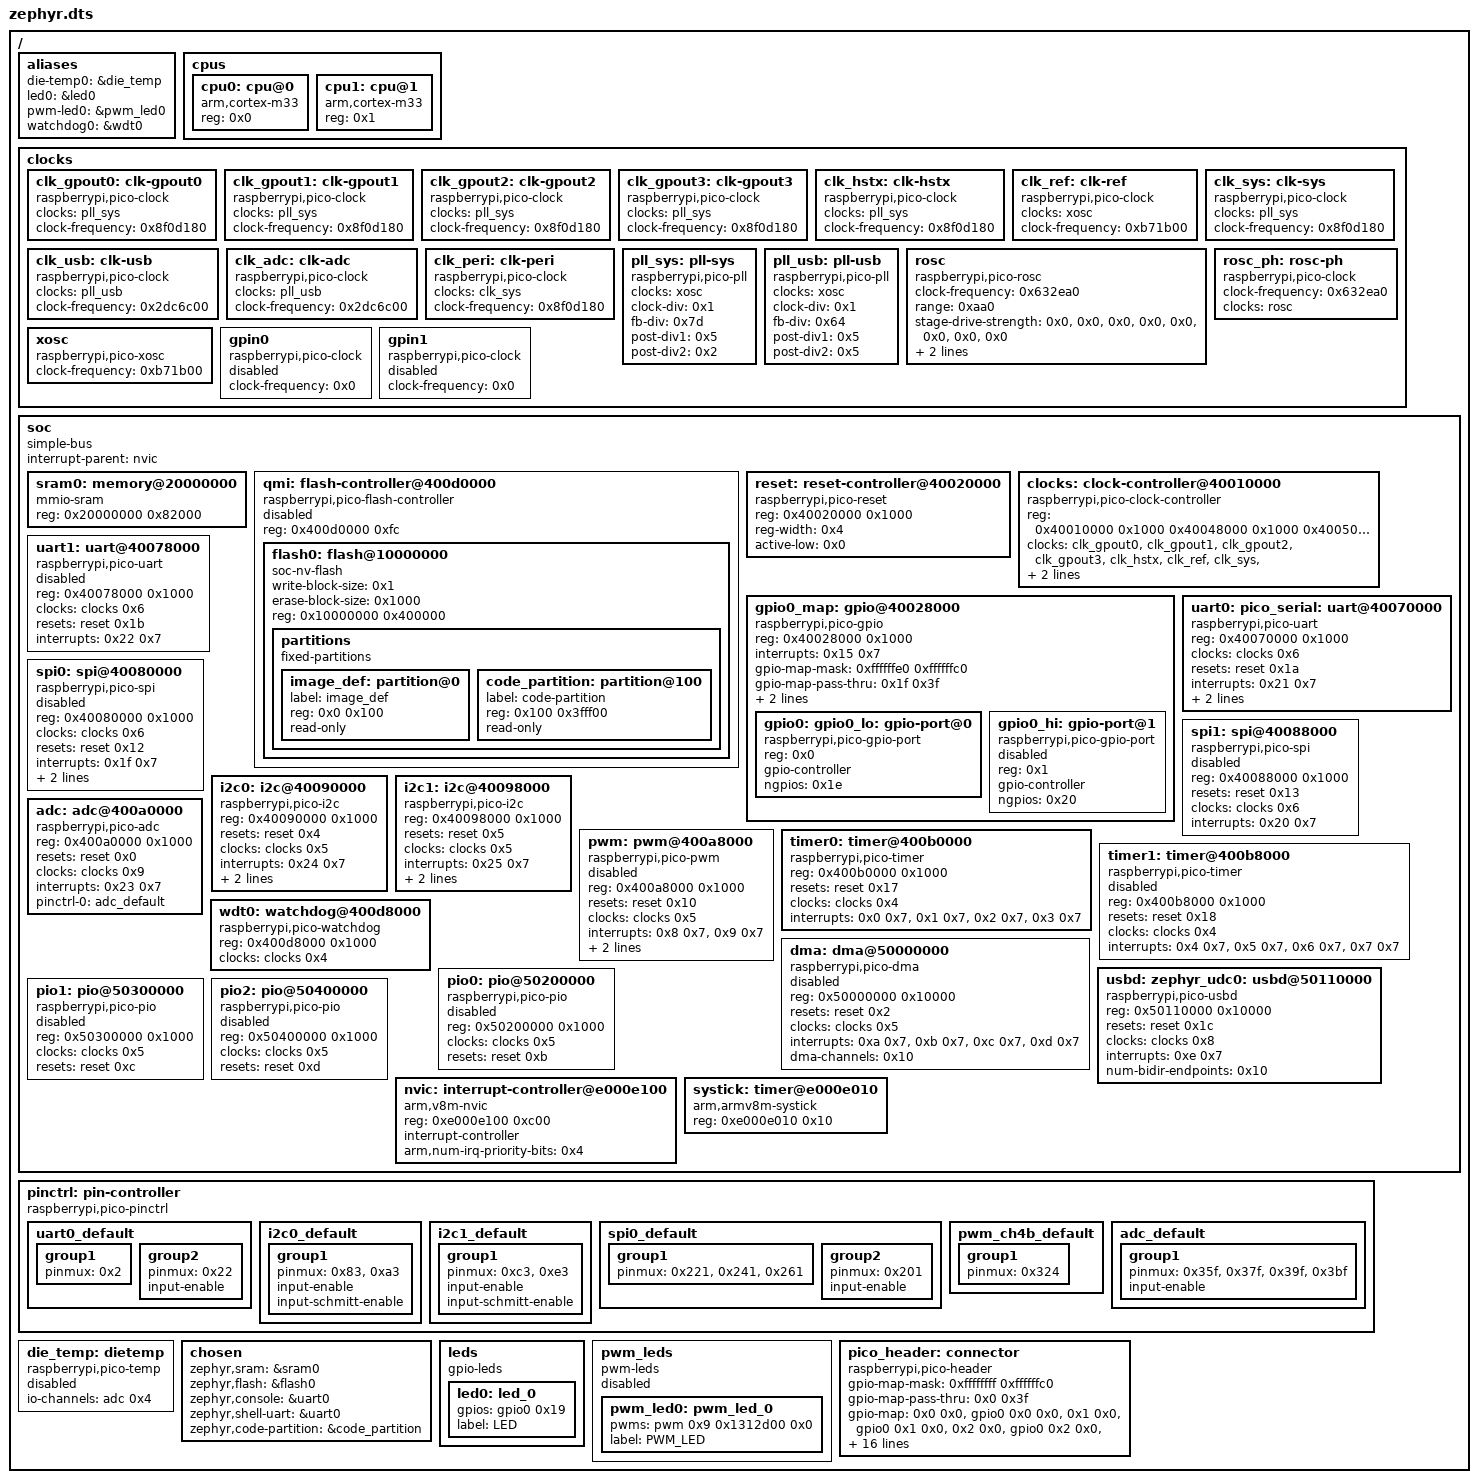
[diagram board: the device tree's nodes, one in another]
/dts-v1/;

/* node '/' defined in deps/zephyr/dts/arm/raspberrypi/rpi_pico/rp2350.dtsi:19 */
/ {
	#address-cells = < 0x1 >; /* in deps/zephyr/dts/common/skeleton.dtsi:10 */
	#size-cells = < 0x1 >;    /* in deps/zephyr/dts/common/skeleton.dtsi:11 */

	/* node '/aliases' defined in deps/zephyr/dts/arm/raspberrypi/rpi_pico/rp2350.dtsi:20 */
	aliases {
		die-temp0 = &die_temp; /* in deps/zephyr/dts/arm/raspberrypi/rpi_pico/rp2350.dtsi:21 */
		led0 = &led0;          /* in deps/zephyr/boards/raspberrypi/common/rpi_pico-led.dtsi:27 */
		pwm-led0 = &pwm_led0;  /* in deps/zephyr/boards/raspberrypi/common/rpi_pico-led.dtsi:28 */
		watchdog0 = &wdt0;     /* in deps/zephyr/boards/raspberrypi/rpi_pico2/rpi_pico2.dtsi:25 */
	};

	/* node '/cpus' defined in deps/zephyr/dts/arm/raspberrypi/rpi_pico/rp2350.dtsi:24 */
	cpus {
		#address-cells = < 0x1 >; /* in deps/zephyr/dts/arm/raspberrypi/rpi_pico/rp2350.dtsi:25 */
		#size-cells = < 0x0 >;    /* in deps/zephyr/dts/arm/raspberrypi/rpi_pico/rp2350.dtsi:26 */

		/* node '/cpus/cpu@0' defined in deps/zephyr/dts/arm/raspberrypi/rpi_pico/rp2350.dtsi:33 */
		cpu0: cpu@0 {
			reg = < 0x0 >;                 /* in deps/zephyr/dts/arm/raspberrypi/rpi_pico/rp2350.dtsi:34 */
			compatible = "arm,cortex-m33"; /* in deps/zephyr/dts/arm/raspberrypi/rpi_pico/m33.dtsi:13 */
		};

		/* node '/cpus/cpu@1' defined in deps/zephyr/dts/arm/raspberrypi/rpi_pico/rp2350.dtsi:37 */
		cpu1: cpu@1 {
			reg = < 0x1 >;                 /* in deps/zephyr/dts/arm/raspberrypi/rpi_pico/rp2350.dtsi:38 */
			compatible = "arm,cortex-m33"; /* in deps/zephyr/dts/arm/raspberrypi/rpi_pico/m33.dtsi:17 */
		};
	};

	/* node '/clocks' defined in deps/zephyr/dts/arm/raspberrypi/rpi_pico/rp2350.dtsi:42 */
	clocks {

		/* node '/clocks/clk-gpout0' defined in deps/zephyr/dts/arm/raspberrypi/rpi_pico/rp2350.dtsi:43 */
		clk_gpout0: clk-gpout0 {
			compatible = "raspberrypi,pico-clock"; /* in deps/zephyr/dts/arm/raspberrypi/rpi_pico/rp2350.dtsi:44 */
			clocks = < &pll_sys >;                 /* in deps/zephyr/dts/arm/raspberrypi/rpi_pico/rp2350.dtsi:45 */
			clock-names = "pll_sys";               /* in deps/zephyr/dts/arm/raspberrypi/rpi_pico/rp2350.dtsi:46 */
			clock-frequency = < 0x8f0d180 >;       /* in deps/zephyr/dts/arm/raspberrypi/rpi_pico/rp2350.dtsi:47 */
			#clock-cells = < 0x0 >;                /* in deps/zephyr/dts/arm/raspberrypi/rpi_pico/rp2350.dtsi:48 */
			#address-cells = < 0x0 >;              /* in deps/zephyr/dts/arm/raspberrypi/rpi_pico/rp2350.dtsi:49 */
			phandle = < 0x7 >;                     /* in deps/zephyr/dts/arm/raspberrypi/rpi_pico/rp2350.dtsi:226 */
		};

		/* node '/clocks/clk-gpout1' defined in deps/zephyr/dts/arm/raspberrypi/rpi_pico/rp2350.dtsi:52 */
		clk_gpout1: clk-gpout1 {
			compatible = "raspberrypi,pico-clock"; /* in deps/zephyr/dts/arm/raspberrypi/rpi_pico/rp2350.dtsi:53 */
			clocks = < &pll_sys >;                 /* in deps/zephyr/dts/arm/raspberrypi/rpi_pico/rp2350.dtsi:54 */
			clock-names = "pll_sys";               /* in deps/zephyr/dts/arm/raspberrypi/rpi_pico/rp2350.dtsi:55 */
			clock-frequency = < 0x8f0d180 >;       /* in deps/zephyr/dts/arm/raspberrypi/rpi_pico/rp2350.dtsi:56 */
			#clock-cells = < 0x0 >;                /* in deps/zephyr/dts/arm/raspberrypi/rpi_pico/rp2350.dtsi:57 */
			phandle = < 0x8 >;                     /* in deps/zephyr/dts/arm/raspberrypi/rpi_pico/rp2350.dtsi:226 */
		};

		/* node '/clocks/clk-gpout2' defined in deps/zephyr/dts/arm/raspberrypi/rpi_pico/rp2350.dtsi:60 */
		clk_gpout2: clk-gpout2 {
			compatible = "raspberrypi,pico-clock"; /* in deps/zephyr/dts/arm/raspberrypi/rpi_pico/rp2350.dtsi:61 */
			clocks = < &pll_sys >;                 /* in deps/zephyr/dts/arm/raspberrypi/rpi_pico/rp2350.dtsi:62 */
			clock-names = "pll_sys";               /* in deps/zephyr/dts/arm/raspberrypi/rpi_pico/rp2350.dtsi:63 */
			clock-frequency = < 0x8f0d180 >;       /* in deps/zephyr/dts/arm/raspberrypi/rpi_pico/rp2350.dtsi:64 */
			#clock-cells = < 0x0 >;                /* in deps/zephyr/dts/arm/raspberrypi/rpi_pico/rp2350.dtsi:65 */
			phandle = < 0x9 >;                     /* in deps/zephyr/dts/arm/raspberrypi/rpi_pico/rp2350.dtsi:226 */
		};

		/* node '/clocks/clk-gpout3' defined in deps/zephyr/dts/arm/raspberrypi/rpi_pico/rp2350.dtsi:68 */
		clk_gpout3: clk-gpout3 {
			compatible = "raspberrypi,pico-clock"; /* in deps/zephyr/dts/arm/raspberrypi/rpi_pico/rp2350.dtsi:69 */
			clocks = < &pll_sys >;                 /* in deps/zephyr/dts/arm/raspberrypi/rpi_pico/rp2350.dtsi:70 */
			clock-names = "pll_sys";               /* in deps/zephyr/dts/arm/raspberrypi/rpi_pico/rp2350.dtsi:71 */
			clock-frequency = < 0x8f0d180 >;       /* in deps/zephyr/dts/arm/raspberrypi/rpi_pico/rp2350.dtsi:72 */
			#clock-cells = < 0x0 >;                /* in deps/zephyr/dts/arm/raspberrypi/rpi_pico/rp2350.dtsi:73 */
			phandle = < 0xa >;                     /* in deps/zephyr/dts/arm/raspberrypi/rpi_pico/rp2350.dtsi:226 */
		};

		/* node '/clocks/clk-hstx' defined in deps/zephyr/dts/arm/raspberrypi/rpi_pico/rp2350.dtsi:76 */
		clk_hstx: clk-hstx {
			compatible = "raspberrypi,pico-clock"; /* in deps/zephyr/dts/arm/raspberrypi/rpi_pico/rp2350.dtsi:77 */
			clocks = < &pll_sys >;                 /* in deps/zephyr/dts/arm/raspberrypi/rpi_pico/rp2350.dtsi:78 */
			clock-names = "pll_sys";               /* in deps/zephyr/dts/arm/raspberrypi/rpi_pico/rp2350.dtsi:79 */
			clock-frequency = < 0x8f0d180 >;       /* in deps/zephyr/dts/arm/raspberrypi/rpi_pico/rp2350.dtsi:80 */
			#clock-cells = < 0x0 >;                /* in deps/zephyr/dts/arm/raspberrypi/rpi_pico/rp2350.dtsi:81 */
			phandle = < 0xb >;                     /* in deps/zephyr/dts/arm/raspberrypi/rpi_pico/rp2350.dtsi:226 */
		};

		/* node '/clocks/clk-ref' defined in deps/zephyr/dts/arm/raspberrypi/rpi_pico/rp2350.dtsi:84 */
		clk_ref: clk-ref {
			compatible = "raspberrypi,pico-clock"; /* in deps/zephyr/dts/arm/raspberrypi/rpi_pico/rp2350.dtsi:85 */
			clocks = < &xosc >;                    /* in deps/zephyr/dts/arm/raspberrypi/rpi_pico/rp2350.dtsi:86 */
			clock-names = "xosc";                  /* in deps/zephyr/dts/arm/raspberrypi/rpi_pico/rp2350.dtsi:87 */
			clock-frequency = < 0xb71b00 >;        /* in deps/zephyr/dts/arm/raspberrypi/rpi_pico/rp2350.dtsi:88 */
			#clock-cells = < 0x0 >;                /* in deps/zephyr/dts/arm/raspberrypi/rpi_pico/rp2350.dtsi:89 */
			phandle = < 0xc >;                     /* in deps/zephyr/dts/arm/raspberrypi/rpi_pico/rp2350.dtsi:226 */
		};

		/* node '/clocks/clk-sys' defined in deps/zephyr/dts/arm/raspberrypi/rpi_pico/rp2350.dtsi:92 */
		clk_sys: clk-sys {
			compatible = "raspberrypi,pico-clock"; /* in deps/zephyr/dts/arm/raspberrypi/rpi_pico/rp2350.dtsi:93 */
			clocks = < &pll_sys >;                 /* in deps/zephyr/dts/arm/raspberrypi/rpi_pico/rp2350.dtsi:94 */
			clock-names = "pll_sys";               /* in deps/zephyr/dts/arm/raspberrypi/rpi_pico/rp2350.dtsi:95 */
			clock-frequency = < 0x8f0d180 >;       /* in deps/zephyr/dts/arm/raspberrypi/rpi_pico/rp2350.dtsi:96 */
			#clock-cells = < 0x0 >;                /* in deps/zephyr/dts/arm/raspberrypi/rpi_pico/rp2350.dtsi:97 */
			phandle = < 0x4 >;                     /* in deps/zephyr/dts/arm/raspberrypi/rpi_pico/rp2350.dtsi:118 */
		};

		/* node '/clocks/clk-usb' defined in deps/zephyr/dts/arm/raspberrypi/rpi_pico/rp2350.dtsi:100 */
		clk_usb: clk-usb {
			compatible = "raspberrypi,pico-clock"; /* in deps/zephyr/dts/arm/raspberrypi/rpi_pico/rp2350.dtsi:101 */
			clocks = < &pll_usb >;                 /* in deps/zephyr/dts/arm/raspberrypi/rpi_pico/rp2350.dtsi:102 */
			clock-names = "pll_usb";               /* in deps/zephyr/dts/arm/raspberrypi/rpi_pico/rp2350.dtsi:103 */
			clock-frequency = < 0x2dc6c00 >;       /* in deps/zephyr/dts/arm/raspberrypi/rpi_pico/rp2350.dtsi:104 */
			#clock-cells = < 0x0 >;                /* in deps/zephyr/dts/arm/raspberrypi/rpi_pico/rp2350.dtsi:105 */
			phandle = < 0xe >;                     /* in deps/zephyr/dts/arm/raspberrypi/rpi_pico/rp2350.dtsi:226 */
		};

		/* node '/clocks/clk-adc' defined in deps/zephyr/dts/arm/raspberrypi/rpi_pico/rp2350.dtsi:108 */
		clk_adc: clk-adc {
			compatible = "raspberrypi,pico-clock"; /* in deps/zephyr/dts/arm/raspberrypi/rpi_pico/rp2350.dtsi:109 */
			clocks = < &pll_usb >;                 /* in deps/zephyr/dts/arm/raspberrypi/rpi_pico/rp2350.dtsi:110 */
			clock-names = "pll_usb";               /* in deps/zephyr/dts/arm/raspberrypi/rpi_pico/rp2350.dtsi:111 */
			clock-frequency = < 0x2dc6c00 >;       /* in deps/zephyr/dts/arm/raspberrypi/rpi_pico/rp2350.dtsi:112 */
			#clock-cells = < 0x0 >;                /* in deps/zephyr/dts/arm/raspberrypi/rpi_pico/rp2350.dtsi:113 */
			phandle = < 0xf >;                     /* in deps/zephyr/dts/arm/raspberrypi/rpi_pico/rp2350.dtsi:226 */
		};

		/* node '/clocks/clk-peri' defined in deps/zephyr/dts/arm/raspberrypi/rpi_pico/rp2350.dtsi:116 */
		clk_peri: clk-peri {
			compatible = "raspberrypi,pico-clock"; /* in deps/zephyr/dts/arm/raspberrypi/rpi_pico/rp2350.dtsi:117 */
			clocks = < &clk_sys >;                 /* in deps/zephyr/dts/arm/raspberrypi/rpi_pico/rp2350.dtsi:118 */
			clock-names = "clk_sys";               /* in deps/zephyr/dts/arm/raspberrypi/rpi_pico/rp2350.dtsi:119 */
			clock-frequency = < 0x8f0d180 >;       /* in deps/zephyr/dts/arm/raspberrypi/rpi_pico/rp2350.dtsi:120 */
			#clock-cells = < 0x0 >;                /* in deps/zephyr/dts/arm/raspberrypi/rpi_pico/rp2350.dtsi:121 */
			phandle = < 0xd >;                     /* in deps/zephyr/dts/arm/raspberrypi/rpi_pico/rp2350.dtsi:226 */
		};

		/* node '/clocks/pll-sys' defined in deps/zephyr/dts/arm/raspberrypi/rpi_pico/rp2350.dtsi:124 */
		pll_sys: pll-sys {
			compatible = "raspberrypi,pico-pll"; /* in deps/zephyr/dts/arm/raspberrypi/rpi_pico/rp2350.dtsi:125 */
			clocks = < &xosc >;                  /* in deps/zephyr/dts/arm/raspberrypi/rpi_pico/rp2350.dtsi:126 */
			clock-names = "xosc";                /* in deps/zephyr/dts/arm/raspberrypi/rpi_pico/rp2350.dtsi:127 */
			clock-div = < 0x1 >;                 /* in deps/zephyr/dts/arm/raspberrypi/rpi_pico/rp2350.dtsi:128 */
			fb-div = < 0x7d >;                   /* in deps/zephyr/dts/arm/raspberrypi/rpi_pico/rp2350.dtsi:129 */
			post-div1 = < 0x5 >;                 /* in deps/zephyr/dts/arm/raspberrypi/rpi_pico/rp2350.dtsi:130 */
			post-div2 = < 0x2 >;                 /* in deps/zephyr/dts/arm/raspberrypi/rpi_pico/rp2350.dtsi:131 */
			#clock-cells = < 0x0 >;              /* in deps/zephyr/dts/arm/raspberrypi/rpi_pico/rp2350.dtsi:132 */
			phandle = < 0x1 >;                   /* in deps/zephyr/dts/arm/raspberrypi/rpi_pico/rp2350.dtsi:45 */
		};

		/* node '/clocks/pll-usb' defined in deps/zephyr/dts/arm/raspberrypi/rpi_pico/rp2350.dtsi:135 */
		pll_usb: pll-usb {
			compatible = "raspberrypi,pico-pll"; /* in deps/zephyr/dts/arm/raspberrypi/rpi_pico/rp2350.dtsi:136 */
			clocks = < &xosc >;                  /* in deps/zephyr/dts/arm/raspberrypi/rpi_pico/rp2350.dtsi:137 */
			clock-names = "xosc";                /* in deps/zephyr/dts/arm/raspberrypi/rpi_pico/rp2350.dtsi:138 */
			clock-div = < 0x1 >;                 /* in deps/zephyr/dts/arm/raspberrypi/rpi_pico/rp2350.dtsi:139 */
			fb-div = < 0x64 >;                   /* in deps/zephyr/dts/arm/raspberrypi/rpi_pico/rp2350.dtsi:140 */
			post-div1 = < 0x5 >;                 /* in deps/zephyr/dts/arm/raspberrypi/rpi_pico/rp2350.dtsi:141 */
			post-div2 = < 0x5 >;                 /* in deps/zephyr/dts/arm/raspberrypi/rpi_pico/rp2350.dtsi:142 */
			#clock-cells = < 0x0 >;              /* in deps/zephyr/dts/arm/raspberrypi/rpi_pico/rp2350.dtsi:143 */
			phandle = < 0x3 >;                   /* in deps/zephyr/dts/arm/raspberrypi/rpi_pico/rp2350.dtsi:102 */
		};

		/* node '/clocks/rosc' defined in deps/zephyr/dts/arm/raspberrypi/rpi_pico/rp2350.dtsi:146 */
		rosc: rosc {
			compatible = "raspberrypi,pico-rosc"; /* in deps/zephyr/dts/arm/raspberrypi/rpi_pico/rp2350.dtsi:147 */
			clock-frequency = < 0x632ea0 >;       /* in deps/zephyr/dts/arm/raspberrypi/rpi_pico/rp2350.dtsi:148 */
			range = < 0xaa0 >;                    /* in deps/zephyr/dts/arm/raspberrypi/rpi_pico/rp2350.dtsi:149 */
			stage-drive-strength = < 0x0 >,
			                       < 0x0 >,
			                       < 0x0 >,
			                       < 0x0 >,
			                       < 0x0 >,
			                       < 0x0 >,
			                       < 0x0 >,
			                       < 0x0 >;       /* in deps/zephyr/dts/arm/raspberrypi/rpi_pico/rp2350.dtsi:150 */
			clock-div = < 0x10 >;                 /* in deps/zephyr/dts/arm/raspberrypi/rpi_pico/rp2350.dtsi:151 */
			phase = < 0x0 >;                      /* in deps/zephyr/dts/arm/raspberrypi/rpi_pico/rp2350.dtsi:152 */
			#clock-cells = < 0x0 >;               /* in deps/zephyr/dts/arm/raspberrypi/rpi_pico/rp2350.dtsi:153 */
			phandle = < 0x5 >;                    /* in deps/zephyr/dts/arm/raspberrypi/rpi_pico/rp2350.dtsi:159 */
		};

		/* node '/clocks/rosc-ph' defined in deps/zephyr/dts/arm/raspberrypi/rpi_pico/rp2350.dtsi:156 */
		rosc_ph: rosc-ph {
			compatible = "raspberrypi,pico-clock"; /* in deps/zephyr/dts/arm/raspberrypi/rpi_pico/rp2350.dtsi:157 */
			clock-frequency = < 0x632ea0 >;        /* in deps/zephyr/dts/arm/raspberrypi/rpi_pico/rp2350.dtsi:158 */
			clocks = < &rosc >;                    /* in deps/zephyr/dts/arm/raspberrypi/rpi_pico/rp2350.dtsi:159 */
			clock-names = "rosc";                  /* in deps/zephyr/dts/arm/raspberrypi/rpi_pico/rp2350.dtsi:160 */
			#clock-cells = < 0x0 >;                /* in deps/zephyr/dts/arm/raspberrypi/rpi_pico/rp2350.dtsi:161 */
			phandle = < 0x10 >;                    /* in deps/zephyr/dts/arm/raspberrypi/rpi_pico/rp2350.dtsi:226 */
		};

		/* node '/clocks/xosc' defined in deps/zephyr/dts/arm/raspberrypi/rpi_pico/rp2350.dtsi:164 */
		xosc: xosc {
			compatible = "raspberrypi,pico-xosc"; /* in deps/zephyr/dts/arm/raspberrypi/rpi_pico/rp2350.dtsi:165 */
			clock-frequency = < 0xb71b00 >;       /* in deps/zephyr/dts/arm/raspberrypi/rpi_pico/rp2350.dtsi:166 */
			#clock-cells = < 0x0 >;               /* in deps/zephyr/dts/arm/raspberrypi/rpi_pico/rp2350.dtsi:167 */
			phandle = < 0x2 >;                    /* in deps/zephyr/dts/arm/raspberrypi/rpi_pico/rp2350.dtsi:86 */
		};

		/* node '/clocks/gpin0' defined in deps/zephyr/dts/arm/raspberrypi/rpi_pico/rp2350.dtsi:170 */
		gpin0: gpin0 {
			compatible = "raspberrypi,pico-clock"; /* in deps/zephyr/dts/arm/raspberrypi/rpi_pico/rp2350.dtsi:171 */
			status = "disabled";                   /* in deps/zephyr/dts/arm/raspberrypi/rpi_pico/rp2350.dtsi:172 */
			clock-frequency = < 0x0 >;             /* in deps/zephyr/dts/arm/raspberrypi/rpi_pico/rp2350.dtsi:173 */
			#clock-cells = < 0x0 >;                /* in deps/zephyr/dts/arm/raspberrypi/rpi_pico/rp2350.dtsi:174 */
			phandle = < 0x11 >;                    /* in deps/zephyr/dts/arm/raspberrypi/rpi_pico/rp2350.dtsi:226 */
		};

		/* node '/clocks/gpin1' defined in deps/zephyr/dts/arm/raspberrypi/rpi_pico/rp2350.dtsi:177 */
		gpin1: gpin1 {
			compatible = "raspberrypi,pico-clock"; /* in deps/zephyr/dts/arm/raspberrypi/rpi_pico/rp2350.dtsi:178 */
			status = "disabled";                   /* in deps/zephyr/dts/arm/raspberrypi/rpi_pico/rp2350.dtsi:179 */
			clock-frequency = < 0x0 >;             /* in deps/zephyr/dts/arm/raspberrypi/rpi_pico/rp2350.dtsi:180 */
			#clock-cells = < 0x0 >;                /* in deps/zephyr/dts/arm/raspberrypi/rpi_pico/rp2350.dtsi:181 */
			phandle = < 0x12 >;                    /* in deps/zephyr/dts/arm/raspberrypi/rpi_pico/rp2350.dtsi:226 */
		};
	};

	/* node '/soc' defined in deps/zephyr/dts/arm/raspberrypi/rpi_pico/rp2350.dtsi:185 */
	soc {
		#address-cells = < 0x1 >;     /* in deps/zephyr/dts/arm/armv8-m.dtsi:7 */
		#size-cells = < 0x1 >;        /* in deps/zephyr/dts/arm/armv8-m.dtsi:8 */
		compatible = "simple-bus";    /* in deps/zephyr/dts/arm/armv8-m.dtsi:9 */
		interrupt-parent = < &nvic >; /* in deps/zephyr/dts/arm/armv8-m.dtsi:10 */
		ranges;                       /* in deps/zephyr/dts/arm/armv8-m.dtsi:11 */

		/* node '/soc/memory@20000000' defined in deps/zephyr/dts/arm/raspberrypi/rpi_pico/rp2350.dtsi:188 */
		sram0: memory@20000000 {
			compatible = "mmio-sram";     /* in deps/zephyr/dts/arm/raspberrypi/rpi_pico/rp2350.dtsi:189 */
			reg = < 0x20000000 0x82000 >; /* in deps/zephyr/dts/arm/raspberrypi/rpi_pico/rp2350.dtsi:190 */
		};

		/* node '/soc/flash-controller@400d0000' defined in deps/zephyr/dts/arm/raspberrypi/rpi_pico/rp2350.dtsi:193 */
		qmi: flash-controller@400d0000 {
			compatible = "raspberrypi,pico-flash-controller"; /* in deps/zephyr/dts/arm/raspberrypi/rpi_pico/rp2350.dtsi:194 */
			reg = < 0x400d0000 0xfc >;                        /* in deps/zephyr/dts/arm/raspberrypi/rpi_pico/rp2350.dtsi:195 */
			#address-cells = < 0x1 >;                         /* in deps/zephyr/dts/arm/raspberrypi/rpi_pico/rp2350.dtsi:197 */
			#size-cells = < 0x1 >;                            /* in deps/zephyr/dts/arm/raspberrypi/rpi_pico/rp2350.dtsi:198 */
			status = "disabled";                              /* in deps/zephyr/dts/arm/raspberrypi/rpi_pico/rp2350.dtsi:205 */

			/* node '/soc/flash-controller@400d0000/flash@10000000' defined in deps/zephyr/dts/arm/raspberrypi/rpi_pico/rp2350.dtsi:200 */
			flash0: flash@10000000 {
				compatible = "soc-nv-flash";   /* in deps/zephyr/dts/arm/raspberrypi/rpi_pico/rp2350.dtsi:201 */
				write-block-size = < 0x1 >;    /* in deps/zephyr/dts/arm/raspberrypi/rpi_pico/rp2350.dtsi:202 */
				erase-block-size = < 0x1000 >; /* in deps/zephyr/dts/arm/raspberrypi/rpi_pico/rp2350.dtsi:203 */
				reg = < 0x10000000 0x400000 >; /* in deps/zephyr/boards/raspberrypi/rpi_pico2/rpi_pico2.dtsi:63 */

				/* node '/soc/flash-controller@400d0000/flash@10000000/partitions' defined in deps/zephyr/boards/raspberrypi/rpi_pico2/rpi_pico2.dtsi:65 */
				partitions {
					compatible = "fixed-partitions"; /* in deps/zephyr/boards/raspberrypi/rpi_pico2/rpi_pico2.dtsi:66 */
					#address-cells = < 0x1 >;        /* in deps/zephyr/boards/raspberrypi/rpi_pico2/rpi_pico2.dtsi:67 */
					#size-cells = < 0x1 >;           /* in deps/zephyr/boards/raspberrypi/rpi_pico2/rpi_pico2.dtsi:68 */

					/* node '/soc/flash-controller@400d0000/flash@10000000/partitions/partition@0' defined in deps/zephyr/boards/raspberrypi/rpi_pico2/rpi_pico2.dtsi:74 */
					image_def: partition@0 {
						label = "image_def"; /* in deps/zephyr/boards/raspberrypi/rpi_pico2/rpi_pico2.dtsi:75 */
						reg = < 0x0 0x100 >; /* in deps/zephyr/boards/raspberrypi/rpi_pico2/rpi_pico2.dtsi:76 */
						read-only;           /* in deps/zephyr/boards/raspberrypi/rpi_pico2/rpi_pico2.dtsi:77 */
					};

					/* node '/soc/flash-controller@400d0000/flash@10000000/partitions/partition@100' defined in deps/zephyr/boards/raspberrypi/rpi_pico2/rpi_pico2.dtsi:85 */
					code_partition: partition@100 {
						label = "code-partition"; /* in deps/zephyr/boards/raspberrypi/rpi_pico2/rpi_pico2.dtsi:86 */
						reg = < 0x100 0x3fff00 >; /* in deps/zephyr/boards/raspberrypi/rpi_pico2/rpi_pico2.dtsi:87 */
						read-only;                /* in deps/zephyr/boards/raspberrypi/rpi_pico2/rpi_pico2.dtsi:88 */
					};
				};
			};
		};

		/* node '/soc/reset-controller@40020000' defined in deps/zephyr/dts/arm/raspberrypi/rpi_pico/rp2350.dtsi:208 */
		reset: reset-controller@40020000 {
			compatible = "raspberrypi,pico-reset"; /* in deps/zephyr/dts/arm/raspberrypi/rpi_pico/rp2350.dtsi:209 */
			reg = < 0x40020000 0x1000 >;           /* in deps/zephyr/dts/arm/raspberrypi/rpi_pico/rp2350.dtsi:210 */
			reg-width = < 0x4 >;                   /* in deps/zephyr/dts/arm/raspberrypi/rpi_pico/rp2350.dtsi:211 */
			active-low = < 0x0 >;                  /* in deps/zephyr/dts/arm/raspberrypi/rpi_pico/rp2350.dtsi:212 */
			#reset-cells = < 0x1 >;                /* in deps/zephyr/dts/arm/raspberrypi/rpi_pico/rp2350.dtsi:213 */
			phandle = < 0x16 >;                    /* in deps/zephyr/dts/arm/raspberrypi/rpi_pico/rp2350.dtsi:274 */
		};

		/* node '/soc/clock-controller@40010000' defined in deps/zephyr/dts/arm/raspberrypi/rpi_pico/rp2350.dtsi:216 */
		clocks: clock-controller@40010000 {
			compatible = "raspberrypi,pico-clock-controller";                                          /* in deps/zephyr/dts/arm/raspberrypi/rpi_pico/rp2350.dtsi:217 */
			reg = < 0x40010000 0x1000 0x40048000 0x1000 0x40050000 0x1000 0x40058000 0x1000 0x400e8000
			        0x1000 >;                                                                          /* in deps/zephyr/dts/arm/raspberrypi/rpi_pico/rp2350.dtsi:218 */
			reg-names = "clocks",
			            "xosc",
			            "pll_sys",
			            "pll_usb",
			            "rosc";                                                                        /* in deps/zephyr/dts/arm/raspberrypi/rpi_pico/rp2350.dtsi:223 */
			#clock-cells = < 0x1 >;                                                                    /* in deps/zephyr/dts/arm/raspberrypi/rpi_pico/rp2350.dtsi:224 */
			status = "okay";                                                                           /* in deps/zephyr/dts/arm/raspberrypi/rpi_pico/rp2350.dtsi:225 */
			clocks = < &clk_gpout0 >,
			         < &clk_gpout1 >,
			         < &clk_gpout2 >,
			         < &clk_gpout3 >,
			         < &clk_hstx >,
			         < &clk_ref >,
			         < &clk_sys >,
			         < &clk_peri >,
			         < &clk_usb >,
			         < &clk_adc >,
			         < &pll_sys >,
			         < &pll_usb >,
			         < &xosc >,
			         < &rosc >,
			         < &rosc_ph >,
			         < &gpin0 >,
			         < &gpin1 >;                                                                       /* in deps/zephyr/dts/arm/raspberrypi/rpi_pico/rp2350.dtsi:226 */
			clock-names = "clk_gpout0",
			              "clk_gpout1",
			              "clk_gpout2",
			              "clk_gpout3",
			              "clk_hstx",
			              "clk_ref",
			              "clk_sys",
			              "clk_peri",
			              "clk_usb",
			              "clk_adc",
			              "pll_sys",
			              "pll_usb",
			              "xosc",
			              "rosc",
			              "rosc_ph",
			              "gpin0",
			              "gpin1";                                                                     /* in deps/zephyr/dts/arm/raspberrypi/rpi_pico/rp2350.dtsi:231 */
			phandle = < 0x15 >;                                                                        /* in deps/zephyr/dts/arm/raspberrypi/rpi_pico/rp2350.dtsi:273 */
		};

		/* node '/soc/gpio@40028000' defined in deps/zephyr/dts/arm/raspberrypi/rpi_pico/rp2350.dtsi:238 */
		gpio0_map: gpio@40028000 {
			compatible = "raspberrypi,pico-gpio";                             /* in deps/zephyr/dts/arm/raspberrypi/rpi_pico/rp2350.dtsi:239 */
			reg = < 0x40028000 0x1000 >;                                      /* in deps/zephyr/dts/arm/raspberrypi/rpi_pico/rp2350.dtsi:240 */
			interrupts = < 0x15 0x7 >;                                        /* in deps/zephyr/dts/arm/raspberrypi/rpi_pico/rp2350.dtsi:241 */
			gpio-map-mask = < 0xffffffe0 0xffffffc0 >;                        /* in deps/zephyr/dts/arm/raspberrypi/rpi_pico/rp2350.dtsi:243 */
			gpio-map-pass-thru = < 0x1f 0x3f >;                               /* in deps/zephyr/dts/arm/raspberrypi/rpi_pico/rp2350.dtsi:244 */
			gpio-map = < 0x0 0x0 &gpio0 0x0 0x0 0x20 0x0 &gpio0_hi 0x0 0x0 >; /* in deps/zephyr/dts/arm/raspberrypi/rpi_pico/rp2350.dtsi:245 */
			#gpio-cells = < 0x2 >;                                            /* in deps/zephyr/dts/arm/raspberrypi/rpi_pico/rp2350.dtsi:247 */
			#address-cells = < 0x1 >;                                         /* in deps/zephyr/dts/arm/raspberrypi/rpi_pico/rp2350.dtsi:248 */
			#size-cells = < 0x0 >;                                            /* in deps/zephyr/dts/arm/raspberrypi/rpi_pico/rp2350.dtsi:249 */

			/* node '/soc/gpio@40028000/gpio-port@0' defined in deps/zephyr/dts/arm/raspberrypi/rpi_pico/rp2350.dtsi:251 */
			gpio0: gpio0_lo: gpio-port@0 {
				compatible = "raspberrypi,pico-gpio-port"; /* in deps/zephyr/dts/arm/raspberrypi/rpi_pico/rp2350.dtsi:252 */
				reg = < 0x0 >;                             /* in deps/zephyr/dts/arm/raspberrypi/rpi_pico/rp2350.dtsi:253 */
				gpio-controller;                           /* in deps/zephyr/dts/arm/raspberrypi/rpi_pico/rp2350.dtsi:255 */
				#gpio-cells = < 0x2 >;                     /* in deps/zephyr/dts/arm/raspberrypi/rpi_pico/rp2350.dtsi:256 */
				ngpios = < 0x1e >;                         /* in deps/zephyr/dts/arm/raspberrypi/rpi_pico/rp2350a.dtsi:4 */
				status = "okay";                           /* in deps/zephyr/boards/raspberrypi/rpi_pico2/rpi_pico2.dtsi:101 */
				phandle = < 0x13 >;                        /* in deps/zephyr/dts/arm/raspberrypi/rpi_pico/rp2350.dtsi:245 */
			};

			/* node '/soc/gpio@40028000/gpio-port@1' defined in deps/zephyr/dts/arm/raspberrypi/rpi_pico/rp2350.dtsi:260 */
			gpio0_hi: gpio-port@1 {
				compatible = "raspberrypi,pico-gpio-port"; /* in deps/zephyr/dts/arm/raspberrypi/rpi_pico/rp2350.dtsi:261 */
				reg = < 0x1 >;                             /* in deps/zephyr/dts/arm/raspberrypi/rpi_pico/rp2350.dtsi:262 */
				status = "disabled";                       /* in deps/zephyr/dts/arm/raspberrypi/rpi_pico/rp2350.dtsi:263 */
				gpio-controller;                           /* in deps/zephyr/dts/arm/raspberrypi/rpi_pico/rp2350.dtsi:264 */
				#gpio-cells = < 0x2 >;                     /* in deps/zephyr/dts/arm/raspberrypi/rpi_pico/rp2350.dtsi:265 */
				ngpios = < 0x20 >;                         /* in deps/zephyr/dts/arm/raspberrypi/rpi_pico/rp2350.dtsi:266 */
				phandle = < 0x14 >;                        /* in deps/zephyr/dts/arm/raspberrypi/rpi_pico/rp2350.dtsi:245 */
			};
		};

		/* node '/soc/uart@40070000' defined in deps/zephyr/dts/arm/raspberrypi/rpi_pico/rp2350.dtsi:270 */
		uart0: pico_serial: uart@40070000 {
			compatible = "raspberrypi,pico-uart",
			             "arm,pl011";             /* in deps/zephyr/dts/arm/raspberrypi/rpi_pico/rp2350.dtsi:271 */
			reg = < 0x40070000 0x1000 >;          /* in deps/zephyr/dts/arm/raspberrypi/rpi_pico/rp2350.dtsi:272 */
			clocks = < &clocks 0x6 >;             /* in deps/zephyr/dts/arm/raspberrypi/rpi_pico/rp2350.dtsi:273 */
			resets = < &reset 0x1a >;             /* in deps/zephyr/dts/arm/raspberrypi/rpi_pico/rp2350.dtsi:274 */
			interrupts = < 0x21 0x7 >;            /* in deps/zephyr/dts/arm/raspberrypi/rpi_pico/rp2350.dtsi:275 */
			interrupt-names = "uart0";            /* in deps/zephyr/dts/arm/raspberrypi/rpi_pico/rp2350.dtsi:276 */
			current-speed = < 0x1c200 >;          /* in deps/zephyr/boards/raspberrypi/rpi_pico2/rpi_pico2.dtsi:94 */
			status = "okay";                      /* in deps/zephyr/boards/raspberrypi/rpi_pico2/rpi_pico2.dtsi:95 */
			pinctrl-0 = < &uart0_default >;       /* in deps/zephyr/boards/raspberrypi/rpi_pico2/rpi_pico2.dtsi:96 */
			pinctrl-names = "default";            /* in deps/zephyr/boards/raspberrypi/rpi_pico2/rpi_pico2.dtsi:97 */
		};

		/* node '/soc/uart@40078000' defined in deps/zephyr/dts/arm/raspberrypi/rpi_pico/rp2350.dtsi:280 */
		uart1: uart@40078000 {
			compatible = "raspberrypi,pico-uart",
			             "arm,pl011";             /* in deps/zephyr/dts/arm/raspberrypi/rpi_pico/rp2350.dtsi:281 */
			reg = < 0x40078000 0x1000 >;          /* in deps/zephyr/dts/arm/raspberrypi/rpi_pico/rp2350.dtsi:282 */
			clocks = < &clocks 0x6 >;             /* in deps/zephyr/dts/arm/raspberrypi/rpi_pico/rp2350.dtsi:283 */
			resets = < &reset 0x1b >;             /* in deps/zephyr/dts/arm/raspberrypi/rpi_pico/rp2350.dtsi:284 */
			interrupts = < 0x22 0x7 >;            /* in deps/zephyr/dts/arm/raspberrypi/rpi_pico/rp2350.dtsi:285 */
			interrupt-names = "uart1";            /* in deps/zephyr/dts/arm/raspberrypi/rpi_pico/rp2350.dtsi:286 */
			status = "disabled";                  /* in deps/zephyr/dts/arm/raspberrypi/rpi_pico/rp2350.dtsi:287 */
		};

		/* node '/soc/spi@40080000' defined in deps/zephyr/dts/arm/raspberrypi/rpi_pico/rp2350.dtsi:290 */
		spi0: spi@40080000 {
			compatible = "raspberrypi,pico-spi",
			             "arm,pl022";            /* in deps/zephyr/dts/arm/raspberrypi/rpi_pico/rp2350.dtsi:291 */
			#address-cells = < 0x1 >;            /* in deps/zephyr/dts/arm/raspberrypi/rpi_pico/rp2350.dtsi:292 */
			#size-cells = < 0x0 >;               /* in deps/zephyr/dts/arm/raspberrypi/rpi_pico/rp2350.dtsi:293 */
			reg = < 0x40080000 0x1000 >;         /* in deps/zephyr/dts/arm/raspberrypi/rpi_pico/rp2350.dtsi:294 */
			clocks = < &clocks 0x6 >;            /* in deps/zephyr/dts/arm/raspberrypi/rpi_pico/rp2350.dtsi:295 */
			resets = < &reset 0x12 >;            /* in deps/zephyr/dts/arm/raspberrypi/rpi_pico/rp2350.dtsi:296 */
			interrupts = < 0x1f 0x7 >;           /* in deps/zephyr/dts/arm/raspberrypi/rpi_pico/rp2350.dtsi:297 */
			interrupt-names = "spi0";            /* in deps/zephyr/dts/arm/raspberrypi/rpi_pico/rp2350.dtsi:298 */
			status = "disabled";                 /* in deps/zephyr/dts/arm/raspberrypi/rpi_pico/rp2350.dtsi:299 */
			clock-frequency = < 0x7a1200 >;      /* in deps/zephyr/boards/raspberrypi/rpi_pico2/rpi_pico2.dtsi:105 */
			pinctrl-0 = < &spi0_default >;       /* in deps/zephyr/boards/raspberrypi/rpi_pico2/rpi_pico2.dtsi:106 */
			pinctrl-names = "default";           /* in deps/zephyr/boards/raspberrypi/rpi_pico2/rpi_pico2.dtsi:107 */
		};

		/* node '/soc/spi@40088000' defined in deps/zephyr/dts/arm/raspberrypi/rpi_pico/rp2350.dtsi:302 */
		spi1: spi@40088000 {
			compatible = "raspberrypi,pico-spi",
			             "arm,pl022";            /* in deps/zephyr/dts/arm/raspberrypi/rpi_pico/rp2350.dtsi:303 */
			#address-cells = < 0x1 >;            /* in deps/zephyr/dts/arm/raspberrypi/rpi_pico/rp2350.dtsi:304 */
			#size-cells = < 0x0 >;               /* in deps/zephyr/dts/arm/raspberrypi/rpi_pico/rp2350.dtsi:305 */
			reg = < 0x40088000 0x1000 >;         /* in deps/zephyr/dts/arm/raspberrypi/rpi_pico/rp2350.dtsi:306 */
			resets = < &reset 0x13 >;            /* in deps/zephyr/dts/arm/raspberrypi/rpi_pico/rp2350.dtsi:307 */
			clocks = < &clocks 0x6 >;            /* in deps/zephyr/dts/arm/raspberrypi/rpi_pico/rp2350.dtsi:308 */
			interrupts = < 0x20 0x7 >;           /* in deps/zephyr/dts/arm/raspberrypi/rpi_pico/rp2350.dtsi:309 */
			interrupt-names = "spi1";            /* in deps/zephyr/dts/arm/raspberrypi/rpi_pico/rp2350.dtsi:310 */
			status = "disabled";                 /* in deps/zephyr/dts/arm/raspberrypi/rpi_pico/rp2350.dtsi:311 */
		};

		/* node '/soc/i2c@40090000' defined in deps/zephyr/dts/arm/raspberrypi/rpi_pico/rp2350.dtsi:314 */
		i2c0: i2c@40090000 {
			compatible = "raspberrypi,pico-i2c",
			             "snps,designware-i2c";  /* in deps/zephyr/dts/arm/raspberrypi/rpi_pico/rp2350.dtsi:315 */
			#address-cells = < 0x1 >;            /* in deps/zephyr/dts/arm/raspberrypi/rpi_pico/rp2350.dtsi:316 */
			#size-cells = < 0x0 >;               /* in deps/zephyr/dts/arm/raspberrypi/rpi_pico/rp2350.dtsi:317 */
			reg = < 0x40090000 0x1000 >;         /* in deps/zephyr/dts/arm/raspberrypi/rpi_pico/rp2350.dtsi:318 */
			resets = < &reset 0x4 >;             /* in deps/zephyr/dts/arm/raspberrypi/rpi_pico/rp2350.dtsi:319 */
			clocks = < &clocks 0x5 >;            /* in deps/zephyr/dts/arm/raspberrypi/rpi_pico/rp2350.dtsi:320 */
			interrupts = < 0x24 0x7 >;           /* in deps/zephyr/dts/arm/raspberrypi/rpi_pico/rp2350.dtsi:321 */
			interrupt-names = "i2c0";            /* in deps/zephyr/dts/arm/raspberrypi/rpi_pico/rp2350.dtsi:322 */
			clock-frequency = < 0x186a0 >;       /* in deps/zephyr/boards/raspberrypi/rpi_pico2/rpi_pico2.dtsi:111 */
			pinctrl-0 = < &i2c0_default >;       /* in deps/zephyr/boards/raspberrypi/rpi_pico2/rpi_pico2.dtsi:112 */
			pinctrl-names = "default";           /* in deps/zephyr/boards/raspberrypi/rpi_pico2/rpi_pico2.dtsi:113 */
			status = "okay";                     /* in deps/zephyr/boards/raspberrypi/rpi_pico2/rpi_pico2.dtsi:114 */
		};

		/* node '/soc/i2c@40098000' defined in deps/zephyr/dts/arm/raspberrypi/rpi_pico/rp2350.dtsi:326 */
		i2c1: i2c@40098000 {
			compatible = "raspberrypi,pico-i2c",
			             "snps,designware-i2c";  /* in deps/zephyr/dts/arm/raspberrypi/rpi_pico/rp2350.dtsi:327 */
			#address-cells = < 0x1 >;            /* in deps/zephyr/dts/arm/raspberrypi/rpi_pico/rp2350.dtsi:328 */
			#size-cells = < 0x0 >;               /* in deps/zephyr/dts/arm/raspberrypi/rpi_pico/rp2350.dtsi:329 */
			reg = < 0x40098000 0x1000 >;         /* in deps/zephyr/dts/arm/raspberrypi/rpi_pico/rp2350.dtsi:330 */
			resets = < &reset 0x5 >;             /* in deps/zephyr/dts/arm/raspberrypi/rpi_pico/rp2350.dtsi:331 */
			clocks = < &clocks 0x5 >;            /* in deps/zephyr/dts/arm/raspberrypi/rpi_pico/rp2350.dtsi:332 */
			interrupts = < 0x25 0x7 >;           /* in deps/zephyr/dts/arm/raspberrypi/rpi_pico/rp2350.dtsi:333 */
			interrupt-names = "i2c1";            /* in deps/zephyr/dts/arm/raspberrypi/rpi_pico/rp2350.dtsi:334 */
			clock-frequency = < 0x186a0 >;       /* in deps/zephyr/boards/raspberrypi/rpi_pico2/rpi_pico2.dtsi:118 */
			pinctrl-0 = < &i2c1_default >;       /* in deps/zephyr/boards/raspberrypi/rpi_pico2/rpi_pico2.dtsi:119 */
			pinctrl-names = "default";           /* in deps/zephyr/boards/raspberrypi/rpi_pico2/rpi_pico2.dtsi:120 */
			status = "okay";                     /* in deps/zephyr/boards/raspberrypi/rpi_pico2/rpi_pico2.dtsi:121 */
		};

		/* node '/soc/adc@400a0000' defined in deps/zephyr/dts/arm/raspberrypi/rpi_pico/rp2350.dtsi:338 */
		adc: adc@400a0000 {
			compatible = "raspberrypi,pico-adc"; /* in deps/zephyr/dts/arm/raspberrypi/rpi_pico/rp2350.dtsi:339 */
			reg = < 0x400a0000 0x1000 >;         /* in deps/zephyr/dts/arm/raspberrypi/rpi_pico/rp2350.dtsi:340 */
			resets = < &reset 0x0 >;             /* in deps/zephyr/dts/arm/raspberrypi/rpi_pico/rp2350.dtsi:341 */
			clocks = < &clocks 0x9 >;            /* in deps/zephyr/dts/arm/raspberrypi/rpi_pico/rp2350.dtsi:342 */
			interrupts = < 0x23 0x7 >;           /* in deps/zephyr/dts/arm/raspberrypi/rpi_pico/rp2350.dtsi:343 */
			interrupt-names = "adc0";            /* in deps/zephyr/dts/arm/raspberrypi/rpi_pico/rp2350.dtsi:344 */
			#io-channel-cells = < 0x1 >;         /* in deps/zephyr/dts/arm/raspberrypi/rpi_pico/rp2350.dtsi:346 */
			pinctrl-0 = < &adc_default >;        /* in deps/zephyr/boards/raspberrypi/rpi_pico2/rpi_pico2.dtsi:125 */
			pinctrl-names = "default";           /* in deps/zephyr/boards/raspberrypi/rpi_pico2/rpi_pico2.dtsi:126 */
			status = "okay";                     /* in deps/zephyr/boards/raspberrypi/rpi_pico2/rpi_pico2.dtsi:127 */
			phandle = < 0x1d >;                  /* in deps/zephyr/dts/arm/raspberrypi/rpi_pico/rp2350a.dtsi:8 */
		};

		/* node '/soc/pwm@400a8000' defined in deps/zephyr/dts/arm/raspberrypi/rpi_pico/rp2350.dtsi:349 */
		pwm: pwm@400a8000 {
			compatible = "raspberrypi,pico-pwm"; /* in deps/zephyr/dts/arm/raspberrypi/rpi_pico/rp2350.dtsi:350 */
			reg = < 0x400a8000 0x1000 >;         /* in deps/zephyr/dts/arm/raspberrypi/rpi_pico/rp2350.dtsi:351 */
			resets = < &reset 0x10 >;            /* in deps/zephyr/dts/arm/raspberrypi/rpi_pico/rp2350.dtsi:352 */
			clocks = < &clocks 0x5 >;            /* in deps/zephyr/dts/arm/raspberrypi/rpi_pico/rp2350.dtsi:353 */
			interrupts = < 0x8 0x7 >,
			             < 0x9 0x7 >;            /* in deps/zephyr/dts/arm/raspberrypi/rpi_pico/rp2350.dtsi:354 */
			interrupt-names = "PWM_IRQ_WRAP_0",
			                  "PWM_IRQ_WRAP_1";  /* in deps/zephyr/dts/arm/raspberrypi/rpi_pico/rp2350.dtsi:356 */
			status = "disabled";                 /* in deps/zephyr/dts/arm/raspberrypi/rpi_pico/rp2350.dtsi:358 */
			#pwm-cells = < 0x3 >;                /* in deps/zephyr/dts/arm/raspberrypi/rpi_pico/rp2350.dtsi:359 */
			pinctrl-0 = < &pwm_ch4b_default >;   /* in deps/zephyr/boards/raspberrypi/rpi_pico2/rpi_pico2.dtsi:131 */
			pinctrl-names = "default";           /* in deps/zephyr/boards/raspberrypi/rpi_pico2/rpi_pico2.dtsi:132 */
			divider-int-0 = < 0xff >;            /* in deps/zephyr/boards/raspberrypi/rpi_pico2/rpi_pico2.dtsi:133 */
			phandle = < 0x1e >;                  /* in deps/zephyr/boards/raspberrypi/common/rpi_pico-led.dtsi:21 */
		};

		/* node '/soc/timer@400b0000' defined in deps/zephyr/dts/arm/raspberrypi/rpi_pico/rp2350.dtsi:362 */
		timer0: timer@400b0000 {
			compatible = "raspberrypi,pico-timer"; /* in deps/zephyr/dts/arm/raspberrypi/rpi_pico/rp2350.dtsi:363 */
			reg = < 0x400b0000 0x1000 >;           /* in deps/zephyr/dts/arm/raspberrypi/rpi_pico/rp2350.dtsi:364 */
			resets = < &reset 0x17 >;              /* in deps/zephyr/dts/arm/raspberrypi/rpi_pico/rp2350.dtsi:365 */
			clocks = < &clocks 0x4 >;              /* in deps/zephyr/dts/arm/raspberrypi/rpi_pico/rp2350.dtsi:366 */
			interrupts = < 0x0 0x7 >,
			             < 0x1 0x7 >,
			             < 0x2 0x7 >,
			             < 0x3 0x7 >;              /* in deps/zephyr/dts/arm/raspberrypi/rpi_pico/rp2350.dtsi:367 */
			interrupt-names = "TIMER0_IRQ_0",
			                  "TIMER0_IRQ_1",
			                  "TIMER0_IRQ_2",
			                  "TIMER0_IRQ_3";      /* in deps/zephyr/dts/arm/raspberrypi/rpi_pico/rp2350.dtsi:371 */
			status = "okay";                       /* in deps/zephyr/boards/raspberrypi/rpi_pico2/rpi_pico2.dtsi:137 */
		};

		/* node '/soc/timer@400b8000' defined in deps/zephyr/dts/arm/raspberrypi/rpi_pico/rp2350.dtsi:378 */
		timer1: timer@400b8000 {
			compatible = "raspberrypi,pico-timer"; /* in deps/zephyr/dts/arm/raspberrypi/rpi_pico/rp2350.dtsi:379 */
			reg = < 0x400b8000 0x1000 >;           /* in deps/zephyr/dts/arm/raspberrypi/rpi_pico/rp2350.dtsi:380 */
			resets = < &reset 0x18 >;              /* in deps/zephyr/dts/arm/raspberrypi/rpi_pico/rp2350.dtsi:381 */
			clocks = < &clocks 0x4 >;              /* in deps/zephyr/dts/arm/raspberrypi/rpi_pico/rp2350.dtsi:382 */
			interrupts = < 0x4 0x7 >,
			             < 0x5 0x7 >,
			             < 0x6 0x7 >,
			             < 0x7 0x7 >;              /* in deps/zephyr/dts/arm/raspberrypi/rpi_pico/rp2350.dtsi:383 */
			interrupt-names = "TIMER1_IRQ_0",
			                  "TIMER1_IRQ_1",
			                  "TIMER1_IRQ_2",
			                  "TIMER1_IRQ_3";      /* in deps/zephyr/dts/arm/raspberrypi/rpi_pico/rp2350.dtsi:387 */
			status = "disabled";                   /* in deps/zephyr/dts/arm/raspberrypi/rpi_pico/rp2350.dtsi:391 */
		};

		/* node '/soc/watchdog@400d8000' defined in deps/zephyr/dts/arm/raspberrypi/rpi_pico/rp2350.dtsi:394 */
		wdt0: watchdog@400d8000 {
			compatible = "raspberrypi,pico-watchdog"; /* in deps/zephyr/dts/arm/raspberrypi/rpi_pico/rp2350.dtsi:395 */
			reg = < 0x400d8000 0x1000 >;              /* in deps/zephyr/dts/arm/raspberrypi/rpi_pico/rp2350.dtsi:396 */
			clocks = < &clocks 0x4 >;                 /* in deps/zephyr/dts/arm/raspberrypi/rpi_pico/rp2350.dtsi:397 */
			status = "okay";                          /* in deps/zephyr/boards/raspberrypi/rpi_pico2/rpi_pico2.dtsi:141 */
		};

		/* node '/soc/dma@50000000' defined in deps/zephyr/dts/arm/raspberrypi/rpi_pico/rp2350.dtsi:401 */
		dma: dma@50000000 {
			compatible = "raspberrypi,pico-dma"; /* in deps/zephyr/dts/arm/raspberrypi/rpi_pico/rp2350.dtsi:402 */
			reg = < 0x50000000 0x10000 >;        /* in deps/zephyr/dts/arm/raspberrypi/rpi_pico/rp2350.dtsi:403 */
			resets = < &reset 0x2 >;             /* in deps/zephyr/dts/arm/raspberrypi/rpi_pico/rp2350.dtsi:404 */
			clocks = < &clocks 0x5 >;            /* in deps/zephyr/dts/arm/raspberrypi/rpi_pico/rp2350.dtsi:405 */
			interrupts = < 0xa 0x7 >,
			             < 0xb 0x7 >,
			             < 0xc 0x7 >,
			             < 0xd 0x7 >;            /* in deps/zephyr/dts/arm/raspberrypi/rpi_pico/rp2350.dtsi:406 */
			interrupt-names = "dma0",
			                  "dma1",
			                  "dma2",
			                  "dma3";            /* in deps/zephyr/dts/arm/raspberrypi/rpi_pico/rp2350.dtsi:410 */
			dma-channels = < 0x10 >;             /* in deps/zephyr/dts/arm/raspberrypi/rpi_pico/rp2350.dtsi:411 */
			status = "disabled";                 /* in deps/zephyr/dts/arm/raspberrypi/rpi_pico/rp2350.dtsi:412 */
			#dma-cells = < 0x3 >;                /* in deps/zephyr/dts/arm/raspberrypi/rpi_pico/rp2350.dtsi:413 */
		};

		/* node '/soc/usbd@50110000' defined in deps/zephyr/dts/arm/raspberrypi/rpi_pico/rp2350.dtsi:416 */
		usbd: zephyr_udc0: usbd@50110000 {
			compatible = "raspberrypi,pico-usbd"; /* in deps/zephyr/dts/arm/raspberrypi/rpi_pico/rp2350.dtsi:417 */
			reg = < 0x50110000 0x10000 >;         /* in deps/zephyr/dts/arm/raspberrypi/rpi_pico/rp2350.dtsi:418 */
			resets = < &reset 0x1c >;             /* in deps/zephyr/dts/arm/raspberrypi/rpi_pico/rp2350.dtsi:419 */
			clocks = < &clocks 0x8 >;             /* in deps/zephyr/dts/arm/raspberrypi/rpi_pico/rp2350.dtsi:420 */
			interrupts = < 0xe 0x7 >;             /* in deps/zephyr/dts/arm/raspberrypi/rpi_pico/rp2350.dtsi:421 */
			interrupt-names = "usbctrl";          /* in deps/zephyr/dts/arm/raspberrypi/rpi_pico/rp2350.dtsi:422 */
			num-bidir-endpoints = < 0x10 >;       /* in deps/zephyr/dts/arm/raspberrypi/rpi_pico/rp2350.dtsi:423 */
			status = "okay";                      /* in deps/zephyr/boards/raspberrypi/rpi_pico2/rpi_pico2.dtsi:145 */
		};

		/* node '/soc/pio@50200000' defined in deps/zephyr/dts/arm/raspberrypi/rpi_pico/rp2350.dtsi:427 */
		pio0: pio@50200000 {
			compatible = "raspberrypi,pico-pio"; /* in deps/zephyr/dts/arm/raspberrypi/rpi_pico/rp2350.dtsi:428 */
			reg = < 0x50200000 0x1000 >;         /* in deps/zephyr/dts/arm/raspberrypi/rpi_pico/rp2350.dtsi:429 */
			clocks = < &clocks 0x5 >;            /* in deps/zephyr/dts/arm/raspberrypi/rpi_pico/rp2350.dtsi:430 */
			resets = < &reset 0xb >;             /* in deps/zephyr/dts/arm/raspberrypi/rpi_pico/rp2350.dtsi:431 */
			status = "disabled";                 /* in deps/zephyr/dts/arm/raspberrypi/rpi_pico/rp2350.dtsi:432 */
		};

		/* node '/soc/pio@50300000' defined in deps/zephyr/dts/arm/raspberrypi/rpi_pico/rp2350.dtsi:435 */
		pio1: pio@50300000 {
			compatible = "raspberrypi,pico-pio"; /* in deps/zephyr/dts/arm/raspberrypi/rpi_pico/rp2350.dtsi:436 */
			reg = < 0x50300000 0x1000 >;         /* in deps/zephyr/dts/arm/raspberrypi/rpi_pico/rp2350.dtsi:437 */
			clocks = < &clocks 0x5 >;            /* in deps/zephyr/dts/arm/raspberrypi/rpi_pico/rp2350.dtsi:438 */
			resets = < &reset 0xc >;             /* in deps/zephyr/dts/arm/raspberrypi/rpi_pico/rp2350.dtsi:439 */
			status = "disabled";                 /* in deps/zephyr/dts/arm/raspberrypi/rpi_pico/rp2350.dtsi:440 */
		};

		/* node '/soc/pio@50400000' defined in deps/zephyr/dts/arm/raspberrypi/rpi_pico/rp2350.dtsi:443 */
		pio2: pio@50400000 {
			compatible = "raspberrypi,pico-pio"; /* in deps/zephyr/dts/arm/raspberrypi/rpi_pico/rp2350.dtsi:444 */
			reg = < 0x50400000 0x1000 >;         /* in deps/zephyr/dts/arm/raspberrypi/rpi_pico/rp2350.dtsi:445 */
			clocks = < &clocks 0x5 >;            /* in deps/zephyr/dts/arm/raspberrypi/rpi_pico/rp2350.dtsi:446 */
			resets = < &reset 0xd >;             /* in deps/zephyr/dts/arm/raspberrypi/rpi_pico/rp2350.dtsi:447 */
			status = "disabled";                 /* in deps/zephyr/dts/arm/raspberrypi/rpi_pico/rp2350.dtsi:448 */
		};

		/* node '/soc/interrupt-controller@e000e100' defined in deps/zephyr/dts/arm/armv8-m.dtsi:13 */
		nvic: interrupt-controller@e000e100 {
			#address-cells = < 0x1 >;            /* in deps/zephyr/dts/arm/armv8-m.dtsi:14 */
			compatible = "arm,v8m-nvic";         /* in deps/zephyr/dts/arm/armv8-m.dtsi:15 */
			reg = < 0xe000e100 0xc00 >;          /* in deps/zephyr/dts/arm/armv8-m.dtsi:16 */
			interrupt-controller;                /* in deps/zephyr/dts/arm/armv8-m.dtsi:17 */
			#interrupt-cells = < 0x2 >;          /* in deps/zephyr/dts/arm/armv8-m.dtsi:18 */
			arm,num-irq-priority-bits = < 0x4 >; /* in deps/zephyr/dts/arm/raspberrypi/rpi_pico/m33.dtsi:21 */
			phandle = < 0x6 >;                   /* in deps/zephyr/dts/arm/armv8-m.dtsi:10 */
		};

		/* node '/soc/timer@e000e010' defined in deps/zephyr/dts/arm/armv8-m.dtsi:21 */
		systick: timer@e000e010 {
			compatible = "arm,armv8m-systick"; /* in deps/zephyr/dts/arm/armv8-m.dtsi:22 */
			reg = < 0xe000e010 0x10 >;         /* in deps/zephyr/dts/arm/armv8-m.dtsi:23 */
		};
	};

	/* node '/pin-controller' defined in deps/zephyr/dts/arm/raspberrypi/rpi_pico/rp2350.dtsi:452 */
	pinctrl: pin-controller {
		compatible = "raspberrypi,pico-pinctrl"; /* in deps/zephyr/dts/arm/raspberrypi/rpi_pico/rp2350.dtsi:453 */
		status = "okay";                         /* in deps/zephyr/dts/arm/raspberrypi/rpi_pico/rp2350.dtsi:454 */

		/* node '/pin-controller/uart0_default' defined in deps/zephyr/boards/raspberrypi/common/rpi_pico-pinctrl-common.dtsi:8 */
		uart0_default: uart0_default {
			phandle = < 0x17 >; /* in deps/zephyr/boards/raspberrypi/rpi_pico2/rpi_pico2.dtsi:96 */

			/* node '/pin-controller/uart0_default/group1' defined in deps/zephyr/boards/raspberrypi/common/rpi_pico-pinctrl-common.dtsi:9 */
			group1 {
				pinmux = < 0x2 >; /* in deps/zephyr/boards/raspberrypi/common/rpi_pico-pinctrl-common.dtsi:10 */
			};

			/* node '/pin-controller/uart0_default/group2' defined in deps/zephyr/boards/raspberrypi/common/rpi_pico-pinctrl-common.dtsi:12 */
			group2 {
				pinmux = < 0x22 >; /* in deps/zephyr/boards/raspberrypi/common/rpi_pico-pinctrl-common.dtsi:13 */
				input-enable;      /* in deps/zephyr/boards/raspberrypi/common/rpi_pico-pinctrl-common.dtsi:14 */
			};
		};

		/* node '/pin-controller/i2c0_default' defined in deps/zephyr/boards/raspberrypi/common/rpi_pico-pinctrl-common.dtsi:18 */
		i2c0_default: i2c0_default {
			phandle = < 0x19 >; /* in deps/zephyr/boards/raspberrypi/rpi_pico2/rpi_pico2.dtsi:112 */

			/* node '/pin-controller/i2c0_default/group1' defined in deps/zephyr/boards/raspberrypi/common/rpi_pico-pinctrl-common.dtsi:19 */
			group1 {
				pinmux = < 0x83 >,
				         < 0xa3 >;    /* in deps/zephyr/boards/raspberrypi/common/rpi_pico-pinctrl-common.dtsi:20 */
				input-enable;         /* in deps/zephyr/boards/raspberrypi/common/rpi_pico-pinctrl-common.dtsi:21 */
				input-schmitt-enable; /* in deps/zephyr/boards/raspberrypi/common/rpi_pico-pinctrl-common.dtsi:22 */
			};
		};

		/* node '/pin-controller/i2c1_default' defined in deps/zephyr/boards/raspberrypi/common/rpi_pico-pinctrl-common.dtsi:26 */
		i2c1_default: i2c1_default {
			phandle = < 0x1a >; /* in deps/zephyr/boards/raspberrypi/rpi_pico2/rpi_pico2.dtsi:119 */

			/* node '/pin-controller/i2c1_default/group1' defined in deps/zephyr/boards/raspberrypi/common/rpi_pico-pinctrl-common.dtsi:27 */
			group1 {
				pinmux = < 0xc3 >,
				         < 0xe3 >;    /* in deps/zephyr/boards/raspberrypi/common/rpi_pico-pinctrl-common.dtsi:28 */
				input-enable;         /* in deps/zephyr/boards/raspberrypi/common/rpi_pico-pinctrl-common.dtsi:29 */
				input-schmitt-enable; /* in deps/zephyr/boards/raspberrypi/common/rpi_pico-pinctrl-common.dtsi:30 */
			};
		};

		/* node '/pin-controller/spi0_default' defined in deps/zephyr/boards/raspberrypi/common/rpi_pico-pinctrl-common.dtsi:34 */
		spi0_default: spi0_default {
			phandle = < 0x18 >; /* in deps/zephyr/boards/raspberrypi/rpi_pico2/rpi_pico2.dtsi:106 */

			/* node '/pin-controller/spi0_default/group1' defined in deps/zephyr/boards/raspberrypi/common/rpi_pico-pinctrl-common.dtsi:35 */
			group1 {
				pinmux = < 0x221 >,
				         < 0x241 >,
				         < 0x261 >; /* in deps/zephyr/boards/raspberrypi/common/rpi_pico-pinctrl-common.dtsi:36 */
			};

			/* node '/pin-controller/spi0_default/group2' defined in deps/zephyr/boards/raspberrypi/common/rpi_pico-pinctrl-common.dtsi:38 */
			group2 {
				pinmux = < 0x201 >; /* in deps/zephyr/boards/raspberrypi/common/rpi_pico-pinctrl-common.dtsi:39 */
				input-enable;       /* in deps/zephyr/boards/raspberrypi/common/rpi_pico-pinctrl-common.dtsi:40 */
			};
		};

		/* node '/pin-controller/pwm_ch4b_default' defined in deps/zephyr/boards/raspberrypi/common/rpi_pico-pinctrl-common.dtsi:44 */
		pwm_ch4b_default: pwm_ch4b_default {
			phandle = < 0x1c >; /* in deps/zephyr/boards/raspberrypi/rpi_pico2/rpi_pico2.dtsi:131 */

			/* node '/pin-controller/pwm_ch4b_default/group1' defined in deps/zephyr/boards/raspberrypi/common/rpi_pico-pinctrl-common.dtsi:45 */
			group1 {
				pinmux = < 0x324 >; /* in deps/zephyr/boards/raspberrypi/common/rpi_pico-pinctrl-common.dtsi:46 */
			};
		};

		/* node '/pin-controller/adc_default' defined in deps/zephyr/boards/raspberrypi/common/rpi_pico-pinctrl-common.dtsi:50 */
		adc_default: adc_default {
			phandle = < 0x1b >; /* in deps/zephyr/boards/raspberrypi/rpi_pico2/rpi_pico2.dtsi:125 */

			/* node '/pin-controller/adc_default/group1' defined in deps/zephyr/boards/raspberrypi/common/rpi_pico-pinctrl-common.dtsi:51 */
			group1 {
				pinmux = < 0x35f >,
				         < 0x37f >,
				         < 0x39f >,
				         < 0x3bf >; /* in deps/zephyr/boards/raspberrypi/common/rpi_pico-pinctrl-common.dtsi:52 */
				input-enable;       /* in deps/zephyr/boards/raspberrypi/common/rpi_pico-pinctrl-common.dtsi:53 */
			};
		};
	};

	/* node '/dietemp' defined in deps/zephyr/dts/arm/raspberrypi/rpi_pico/rp2350.dtsi:457 */
	die_temp: dietemp {
		compatible = "raspberrypi,pico-temp"; /* in deps/zephyr/dts/arm/raspberrypi/rpi_pico/rp2350.dtsi:458 */
		status = "disabled";                  /* in deps/zephyr/dts/arm/raspberrypi/rpi_pico/rp2350.dtsi:459 */
		io-channels = < &adc 0x4 >;           /* in deps/zephyr/dts/arm/raspberrypi/rpi_pico/rp2350a.dtsi:8 */
	};

	/* node '/chosen' defined in deps/zephyr/dts/common/skeleton.dtsi:12 */
	chosen {
		zephyr,sram = &sram0;                    /* in deps/zephyr/boards/raspberrypi/rpi_pico2/rpi_pico2.dtsi:17 */
		zephyr,flash = &flash0;                  /* in deps/zephyr/boards/raspberrypi/rpi_pico2/rpi_pico2.dtsi:18 */
		zephyr,console = &uart0;                 /* in deps/zephyr/boards/raspberrypi/rpi_pico2/rpi_pico2.dtsi:19 */
		zephyr,shell-uart = &uart0;              /* in deps/zephyr/boards/raspberrypi/rpi_pico2/rpi_pico2.dtsi:20 */
		zephyr,code-partition = &code_partition; /* in deps/zephyr/boards/raspberrypi/rpi_pico2/rpi_pico2.dtsi:21 */
	};

	/* node '/leds' defined in deps/zephyr/boards/raspberrypi/common/rpi_pico-led.dtsi:9 */
	leds {
		compatible = "gpio-leds"; /* in deps/zephyr/boards/raspberrypi/common/rpi_pico-led.dtsi:10 */

		/* node '/leds/led_0' defined in deps/zephyr/boards/raspberrypi/common/rpi_pico-led.dtsi:11 */
		led0: led_0 {
			gpios = < &gpio0 0x19 0x0 >; /* in deps/zephyr/boards/raspberrypi/common/rpi_pico-led.dtsi:12 */
			label = "LED";               /* in deps/zephyr/boards/raspberrypi/common/rpi_pico-led.dtsi:13 */
		};
	};

	/* node '/pwm_leds' defined in deps/zephyr/boards/raspberrypi/common/rpi_pico-led.dtsi:17 */
	pwm_leds {
		compatible = "pwm-leds"; /* in deps/zephyr/boards/raspberrypi/common/rpi_pico-led.dtsi:18 */
		status = "disabled";     /* in deps/zephyr/boards/raspberrypi/common/rpi_pico-led.dtsi:19 */

		/* node '/pwm_leds/pwm_led_0' defined in deps/zephyr/boards/raspberrypi/common/rpi_pico-led.dtsi:20 */
		pwm_led0: pwm_led_0 {
			pwms = < &pwm 0x9 0x1312d00 0x0 >; /* in deps/zephyr/boards/raspberrypi/common/rpi_pico-led.dtsi:21 */
			label = "PWM_LED";                 /* in deps/zephyr/boards/raspberrypi/common/rpi_pico-led.dtsi:22 */
		};
	};

	/* node '/connector' defined in deps/zephyr/boards/raspberrypi/rpi_pico2/rpi_pico2.dtsi:28 */
	pico_header: connector {
		compatible = "raspberrypi,pico-header";    /* in deps/zephyr/boards/raspberrypi/rpi_pico2/rpi_pico2.dtsi:29 */
		#gpio-cells = < 0x2 >;                     /* in deps/zephyr/boards/raspberrypi/rpi_pico2/rpi_pico2.dtsi:30 */
		gpio-map-mask = < 0xffffffff 0xffffffc0 >; /* in deps/zephyr/boards/raspberrypi/rpi_pico2/rpi_pico2.dtsi:31 */
		gpio-map-pass-thru = < 0x0 0x3f >;         /* in deps/zephyr/boards/raspberrypi/rpi_pico2/rpi_pico2.dtsi:32 */
		gpio-map = < 0x0 0x0 &gpio0 0x0 0x0 >,
		           < 0x1 0x0 &gpio0 0x1 0x0 >,
		           < 0x2 0x0 &gpio0 0x2 0x0 >,
		           < 0x3 0x0 &gpio0 0x3 0x0 >,
		           < 0x4 0x0 &gpio0 0x4 0x0 >,
		           < 0x5 0x0 &gpio0 0x5 0x0 >,
		           < 0x6 0x0 &gpio0 0x6 0x0 >,
		           < 0x7 0x0 &gpio0 0x7 0x0 >,
		           < 0x8 0x0 &gpio0 0x8 0x0 >,
		           < 0x9 0x0 &gpio0 0x9 0x0 >,
		           < 0xa 0x0 &gpio0 0xa 0x0 >,
		           < 0xb 0x0 &gpio0 0xb 0x0 >,
		           < 0xc 0x0 &gpio0 0xc 0x0 >,
		           < 0xd 0x0 &gpio0 0xd 0x0 >,
		           < 0xe 0x0 &gpio0 0xe 0x0 >,
		           < 0xf 0x0 &gpio0 0xf 0x0 >,
		           < 0x10 0x0 &gpio0 0x10 0x0 >,
		           < 0x11 0x0 &gpio0 0x11 0x0 >,
		           < 0x12 0x0 &gpio0 0x12 0x0 >,
		           < 0x13 0x0 &gpio0 0x13 0x0 >,
		           < 0x14 0x0 &gpio0 0x14 0x0 >,
		           < 0x15 0x0 &gpio0 0x15 0x0 >,
		           < 0x16 0x0 &gpio0 0x16 0x0 >,
		           < 0x1a 0x0 &gpio0 0x1a 0x0 >,
		           < 0x1b 0x0 &gpio0 0x1b 0x0 >,
		           < 0x1c 0x0 &gpio0 0x1c 0x0 >;   /* in deps/zephyr/boards/raspberrypi/rpi_pico2/rpi_pico2.dtsi:33 */
	};
};
